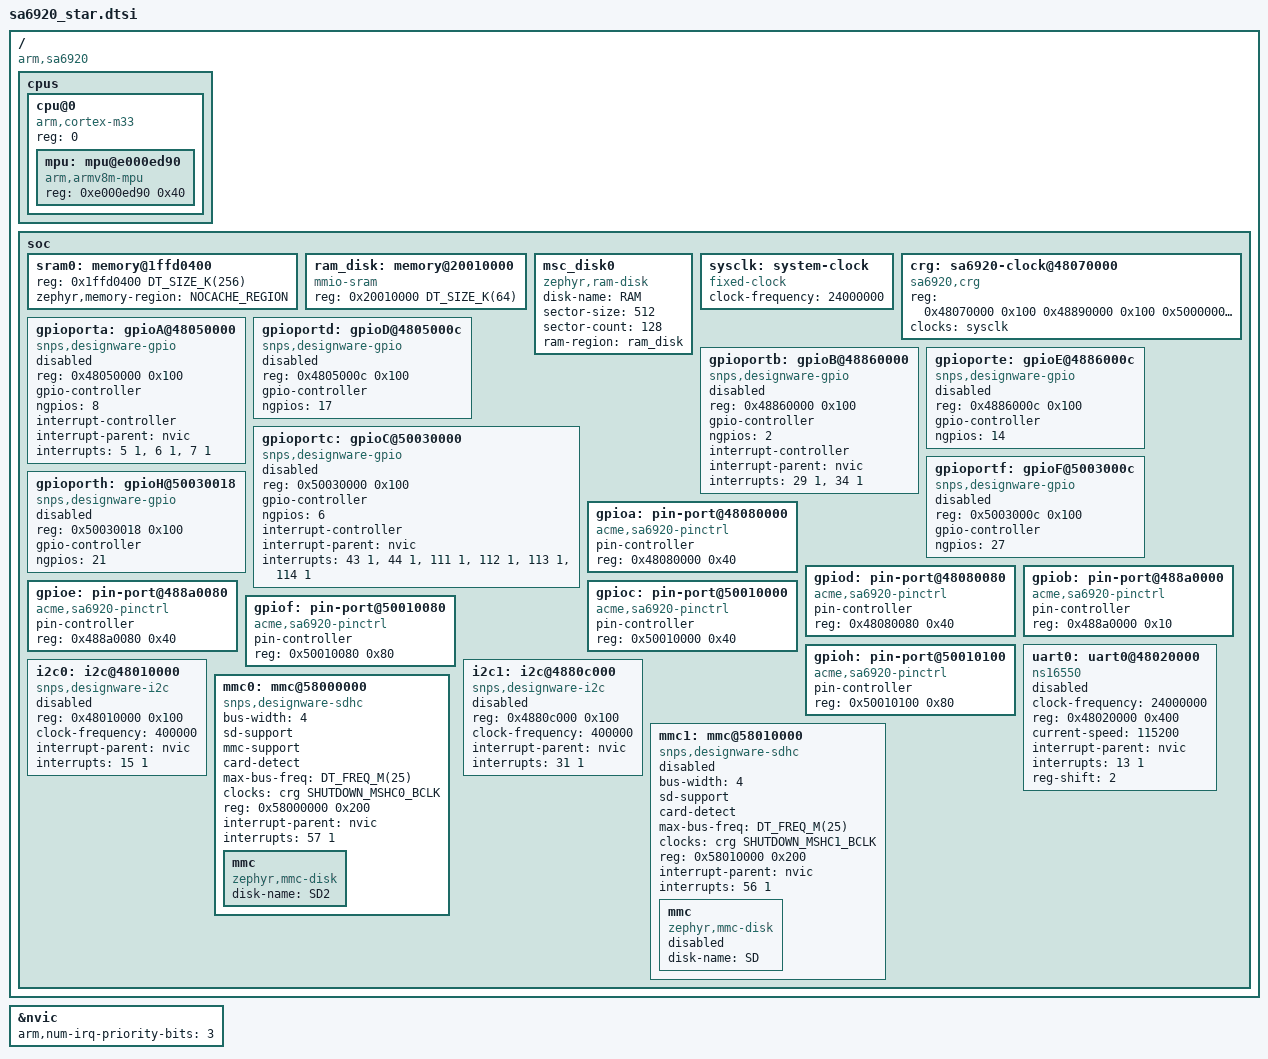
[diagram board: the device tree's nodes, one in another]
/*
 * Copyright (c)  2021 Dean Weiten <dmw@weiten.com>
 *
 * SPDX-License-Identifier: Apache-2.0
 */



#include <arm/armv8-m.dtsi>
#include <mem.h>
#include <freq.h>
#include <zephyr/dt-bindings/gpio/gpio.h>
#include <zephyr/dt-bindings/i2c/i2c.h>
#include <zephyr/dt-bindings/clock/sa6920_clock.h>
#include <zephyr/dt-bindings/pinctrl/smartbond-pinctrl.h>

/ {
	compatible = "arm,sa6920";
	#address-cells = <1>;
	#size-cells = <1>;

	cpus: cpus {
		#address-cells = <1>;
		#size-cells = <0>;

		cpu@0 {
			device_type = "cpu";
			compatible = "arm,cortex-m33";
			reg = <0>;
			#address-cells = <1>;
			#size-cells = <1>;

			mpu: mpu@e000ed90 {
				compatible = "arm,armv8m-mpu";
				reg = <0xe000ed90 0x40>;
			};
		};
	};

	soc {
		sram0: memory@1ffd0400 {
			reg = <0x1ffd0400 DT_SIZE_K(256)>;
			zephyr,memory-region = "NOCACHE_REGION";
		};

		ram_disk: memory@20010000 {
			compatible = "mmio-sram";
			
			reg = <0x20010000 DT_SIZE_K(64)>;
		};

		msc_disk0 {
		status="okay";
		compatible = "zephyr,ram-disk";
		/* Sample, to make things easier, mounts all FAT
		 * systems at "SD".
		 */
		disk-name = "RAM";
		/* Disk size is 64kB, 128 sectors of 512B, the minimal
		 * required by FAT FS.
		 */
		sector-size = <512>;
		sector-count = <128>;
		/* Here is the reference to the memory reserved for our
		 * disk using a phandle; note that we reference the
		 * region by label we have defined it above.
		 */
		ram-region = <&ram_disk>;
	};

		sysclk: system-clock {
			compatible = "fixed-clock";
			clock-frequency = <24000000>;
			#clock-cells = <0>;
		};
			
		crg: sa6920-clock@48070000 {
			compatible = "sa6920,crg";
			reg = <0x48070000 0x100 0x48890000 0x100 0x50000000  0x100 0x480A0010 0x4>;
			#clock-cells = <1>;
			clocks = <&sysclk>;
			status = "okay";
		};

		gpioporta: gpioA@48050000 {
			compatible = "snps,designware-gpio";
			reg = <0x48050000 0x100>;
			#address-cells = <1>;
			#size-cells = <0>;
			gpio-controller;
			#gpio-cells = <2>;
			ngpios = <8>;
			#address-cells = <1>;
			interrupt-controller;
			#interrupt-cells = <2>;
			interrupt-parent = <&nvic>;
			interrupts = <5 1>,
						<6 1>,
						<7 1>;
			status = "disabled";
		};
		gpioportd: gpioD@4805000c {
			compatible = "snps,designware-gpio";
			reg = <0x4805000c 0x100>;
			#address-cells = <1>;
			#size-cells = <0>;
			gpio-controller;
			#gpio-cells = <2>;
			ngpios = <17>;
			#address-cells = <1>;
			status = "disabled";
		};
		gpioportb: gpioB@48860000 {
			compatible = "snps,designware-gpio";
			reg = <0x48860000 0x100>;
			#address-cells = <1>;
			#size-cells = <0>;
			gpio-controller;
			#gpio-cells = <2>;
			ngpios = <2>;
			#address-cells = <1>;
			interrupt-controller;
			#interrupt-cells = <2>;
			interrupt-parent = <&nvic>;
			interrupts = <29 1>,
						 <34 1>;
			status = "disabled";
		};
		gpioporte: gpioE@4886000c {
			compatible = "snps,designware-gpio";
			reg = <0x4886000c 0x100>;
			#address-cells = <1>;
			#size-cells = <0>;
			gpio-controller;
			#gpio-cells = <2>;
			ngpios = <14>;
			#address-cells = <1>;
			status = "disabled";
		};
		gpioportc: gpioC@50030000 {
			compatible = "snps,designware-gpio";
			reg = <0x50030000 0x100>;
			#address-cells = <1>;
			#size-cells = <0>;
			gpio-controller;
			#gpio-cells = <2>;
			ngpios = <6>;
			#address-cells = <1>;
			interrupt-controller;
			#interrupt-cells = <2>;
			interrupt-parent = <&nvic>;
			interrupts = <43 1>,
			 			 <44 1>,
						 <111 1>,
						 <112 1>,
						 <113 1>,
						 <114 1>;
			status = "disabled";
		};
		gpioportf: gpioF@5003000c {
			compatible = "snps,designware-gpio";
			reg = <0x5003000c 0x100>;
			#address-cells = <1>;
			#size-cells = <0>;
			gpio-controller;
			#gpio-cells = <2>;
			ngpios = <27>;
			#address-cells = <1>;
			status = "disabled";
		};
		gpioporth: gpioH@50030018 {
			compatible = "snps,designware-gpio";
			reg = <0x50030018 0x100>;
			#address-cells = <1>;
			#size-cells = <0>;
			gpio-controller;
			#gpio-cells = <2>;
			ngpios = <21>;
			#address-cells = <1>;
			status = "disabled";
		};

		gpioa: pin-port@48080000 {
			compatible = "acme,sa6920-pinctrl";
			pin-controller;
			reg = <0x48080000 0x40>;
        };

		gpiod: pin-port@48080080 {
			compatible = "acme,sa6920-pinctrl";
			pin-controller;
			reg = <0x48080080 0x40>;
        };
		gpiob: pin-port@488a0000 {
			compatible = "acme,sa6920-pinctrl";
			pin-controller;
			reg = <0x488a0000 0x10>;
        };
		gpioe: pin-port@488a0080 {
			compatible = "acme,sa6920-pinctrl";
			pin-controller;
			reg = <0x488a0080 0x40>;
        };
		gpioc: pin-port@50010000 {
			compatible = "acme,sa6920-pinctrl";
			pin-controller;
			reg = <0x50010000 0x40>;
        };
		gpiof: pin-port@50010080 {
			compatible = "acme,sa6920-pinctrl";
			pin-controller;
			reg = <0x50010080 0x80>;
        };
		gpioh: pin-port@50010100 {
			compatible = "acme,sa6920-pinctrl";
			pin-controller;
			reg = <0x50010100 0x80>;
        };

        uart0: uart0@48020000 {
            compatible = "ns16550";
            clock-frequency = <24000000>;
            reg = <0x48020000 0x400>;
            current-speed = <115200>;
            interrupt-parent = <&nvic>;
            interrupts = <13 1>;
            reg-shift = <2>;
            status = "disabled";
        };

		i2c0: i2c@48010000 {
			compatible = "snps,designware-i2c";
			#address-cells = <1>;
			#size-cells = <0>;
			reg = <0x48010000 0x100>;
			clock-frequency = <400000>;
			interrupt-parent = <&nvic>;
			interrupts = <15 1>;
			status = "disabled";
		};

		i2c1: i2c@4880c000 {
			compatible = "snps,designware-i2c";
			#address-cells = <1>;
			#size-cells = <0>;
			reg = <0x4880c000 0x100>;
			clock-frequency = <400000>;
			interrupt-parent = <&nvic>;
			interrupts = <31 1>;
			status = "disabled";
		};

		mmc0: mmc@58000000 {
			compatible = "snps,designware-sdhc";
			bus-width = <4>;
			sd-support;
			mmc-support;
			card-detect;
			max-bus-freq = <DT_FREQ_M(25)>;
			clocks = <&crg SHUTDOWN_MSHC0_BCLK>;
			reg = <0x58000000 0x200>;
			interrupt-parent = <&nvic>;
			interrupts = <57 1>;
			
			status = "okay";
			mmc {
				compatible = "zephyr,mmc-disk";
				disk-name = "SD2";
				status = "okay";
			};

		};

		mmc1: mmc@58010000 {
			compatible = "snps,designware-sdhc";
			bus-width = <4>;
			sd-support;
			card-detect;
			max-bus-freq = <DT_FREQ_M(25)>;
			clocks = <&crg SHUTDOWN_MSHC1_BCLK>;
			reg = <0x58010000 0x200>;
			interrupt-parent = <&nvic>;
			interrupts = <56 1>;
			
			status = "disabled";
			mmc {
				compatible = "zephyr,mmc-disk";
				disk-name = "SD";
				status = "disabled";
			};

		};
	};

	

};

&nvic {
	arm,num-irq-priority-bits = <3>;
};
